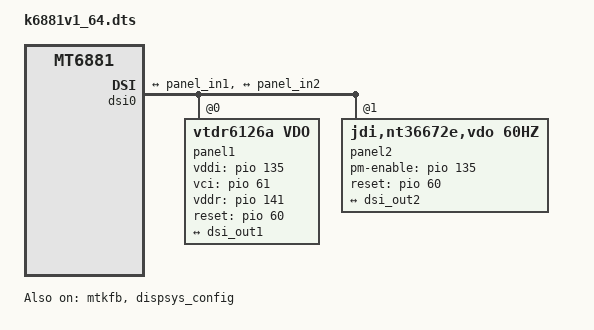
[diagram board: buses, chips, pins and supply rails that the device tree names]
// SPDX-License-Identifier: (GPL-2.0 OR MIT)
/*
 * Copyright (c) 2024 MediaTek Inc.
 */

/dts-v1/;
/plugin/;
#include <dt-bindings/interrupt-controller/arm-gic.h>
#include <dt-bindings/interrupt-controller/irq.h>
#include <dt-bindings/phy/phy.h>
#include <dt-bindings/pinctrl/mt6881-pinfunc.h>

/* chosen */
&chosen {
	bootargs = "console=tty0 console=ttyS0,921600n1 root=/dev/ram vmalloc=400M cma=64M \
8250.nr_uarts=4 kmemleak=off kasan=off \
loglevel=8 \
androidboot.hardware=mt6881 \
earlycon=uart8250,mmio32,0x11001000 \
initcall_debug=1 \
kvm-arm.mode=none \
arm64.nopauth arm64.nosme arm64.nosve";
};

&timer {
	clock-frequency = <0x00000002 0xafbef362>;
};

&mtkfb {
	pinctrl-names = "lcd_bias_enp0_gpio",
		"lcd_bias_enn0_gpio",
		"lcm_vddi_out0_gpio",
		"lcm_vci_out0_gpio",
		"lcm_vddr_out0_gpio",
		"lcm_rst_out0_gpio",
		"mode_te_te",
		"lcm_led_en0_gpio";
	pinctrl-0 = <&mtkfb_pins_lcd_bias_enp0>;
	pinctrl-1 = <&mtkfb_pins_lcd_bias_enn0>;
	pinctrl-2 = <&mtkfb_pins_lcm_vddi_out0_gpio>;
	pinctrl-3 = <&mtkfb_pins_lcm_vci_out0_gpio>;
	pinctrl-4 = <&mtkfb_pins_lcm_vddr_out0_gpio>;
	pinctrl-5 = <&mtkfb_pins_lcm_rst_out0_gpio>;
	pinctrl-6 = <&mtkfb_pins_lcm_dsi_te>;
	pinctrl-7 = <&mtkfb_pins_lcm_led_en0>;

	status = "okay";
};

&dispsys_config {
	pinctrl-names = "mode_te_te";
	pinctrl-0 = <&mtkfb_pins_lcm_dsi_te>;
	status = "okay";
};

&mt6363keys {
	pinctrl-names = "kpcol0_mode";
	pinctrl-0 = <&kpcol0_pins_gpio_mode>;
	home2 {
		linux,keycodes = <114>;
		wakeup-source;
	};
};

&pio {
	kpcol0_pins_gpio_mode: gpio-mode {
		pins-cmd-dat {
			pinmux = <PINMUX_GPIO16__FUNC_GPIO16>;
			input-enable;
		};
	};

	mtkfb_pins_lcd_bias_enp0: lcd-bias-enp0-gpio {
		pins-cmd-dat {
			pinmux = <PINMUX_GPIO135__FUNC_GPIO135>;
			slew-rate = <1>;
			output-low;
		};
	};

	mtkfb_pins_lcd_bias_enn0: lcd-bias-enn0-gpio {
		pins-cmd-dat {
			pinmux = <PINMUX_GPIO135__FUNC_GPIO135>;
			slew-rate = <1>;
			output-low;
		};
	};

	mtkfb_pins_lcm_vddi_out0_gpio: lcd-vddi-out0-gpio {
		pins-cmd-dat {
			pinmux = <PINMUX_GPIO135__FUNC_GPIO135>;
			slew-rate = <1>;
			output-low;
		};
	};

	mtkfb_pins_lcm_vci_out0_gpio: lcd-vci-out0-gpio {
		pins-cmd-dat {
			pinmux = <PINMUX_GPIO61__FUNC_GPIO61>;
			slew-rate = <1>;
			output-low;
		};
	};

	mtkfb_pins_lcm_vddr_out0_gpio: lcd-vddr-out0-gpio {
		pins-cmd-dat {
			pinmux = <PINMUX_GPIO141__FUNC_GPIO141>;
			slew-rate = <1>;
			output-low;
		};
	};

	mtkfb_pins_lcm_rst_out0_gpio: lcm-rst-out0-gpio {
		pins-cmd-dat {
			pinmux = <PINMUX_GPIO60__FUNC_GPIO60>;
			slew-rate = <1>;
			output-low;
		};
	};
	mtkfb_pins_lcm_dsi_te: lcm-dsi-te {
		pins-cmd-dat {
			pinmux = <PINMUX_GPIO59__FUNC_DSI_TE>;
		};
	};

	mtkfb_pins_lcm_led_en0: lcm-led-en0-gpio {
		pins-cmd-dat {
			pinmux = <PINMUX_GPIO135__FUNC_GPIO135>;
			slew-rate = <1>;
			output-low;
		};
	};
};

&dsi0 {
	status = "okay";
	#address-cells = <1>;
	#size-cells = <0>;
	panel1@0 {
		compatible = "vtdr6126a,vdo";
		reg = <0>;
		vddi-gpios = <&pio 135 0>;
		vci-gpios = <&pio 61 0>;
		vddr-gpios = <&pio 141 0>;
		reset-gpios = <&pio 60 0>;
		pinctrl-names = "default";
		port {
			panel_in1: endpoint {
				remote-endpoint = <&dsi_out1>;
			};
		};
	};
	panel2@1 {
	    compatible = "jdi,nt36672e,vdo,60hz";
		reg = <1>;
		pm-enable-gpios = <&pio 135 0>;
		reset-gpios = <&pio 60 0>;
		gate-ic = <4831>;
		pinctrl-names = "default";
		port {
			panel_in2: endpoint {
				remote-endpoint = <&dsi_out2>;
			};
		};
	};
	ports {
		port {
			dsi_out1: endpoint@0 {
				remote-endpoint = <&panel_in1>;
			};
			dsi_out2: endpoint@1 {
				remote-endpoint = <&panel_in2>;
			};
		};
	};
};

/* MD/RF always-on setting */
&mt6363_vbuck5 {
	regulator-always-on;
};

&mt6363_vbuck6 {
	regulator-always-on;
};

&mt6363_vcn15 {
	regulator-always-on;
};

&mt6363_vrf12 {
	regulator-always-on;
};

&mt6363_vsram_digrf {
	regulator-always-on;
};

&mt6363_vsram_modem {
	regulator-always-on;
};

#include <k6881v1_64/cust.dtsi>
#include "mediatek/cust_mt6881_camera_v4l2.dtsi"
#include "mediatek/cust_mt6881_touch_1080x2400_mult.dtsi"
/*End of this file, DO NOT ADD ANYTHING HERE*/
